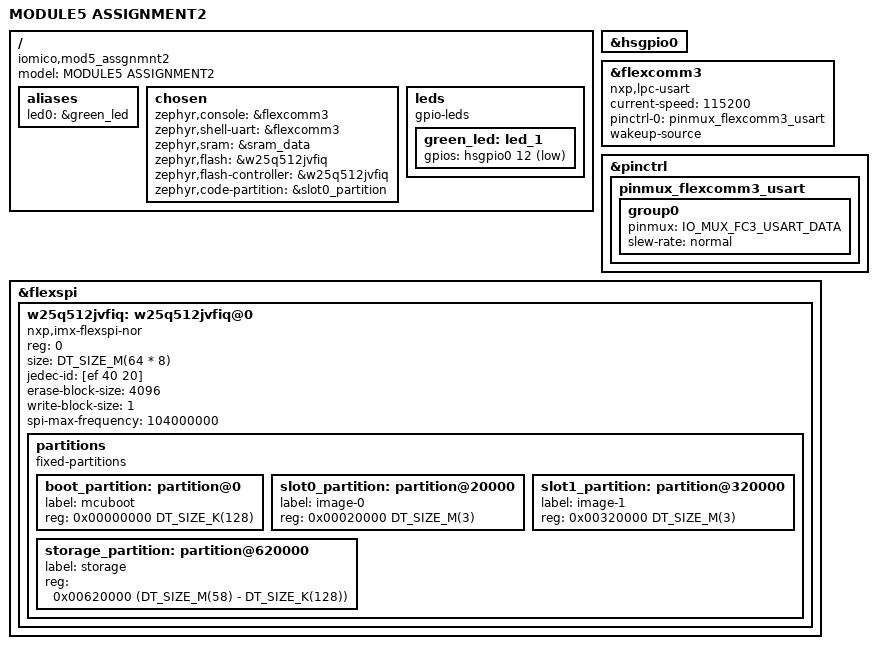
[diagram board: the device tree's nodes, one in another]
/dts-v1/;

#include <nxp/nxp_rw6xx.dtsi>
#include <nxp/rw/RW612-pinctrl.h>

/ {
	model = "MODULE5 ASSIGNMENT2";
	compatible = "iomico,mod5_assgnmnt2";

	aliases {
		led0 = &green_led;
	};

	chosen {
		zephyr,console = &flexcomm3;
		zephyr,shell-uart = &flexcomm3;
	};

	chosen {
		zephyr,sram = &sram_data;
		zephyr,flash = &w25q512jvfiq;
		zephyr,flash-controller = &w25q512jvfiq;
		zephyr,code-partition = &slot0_partition;
		zephyr,console = &flexcomm3;
	};

	leds {
		compatible = "gpio-leds";
		green_led: led_1 {
			gpios = <&hsgpio0 12 GPIO_ACTIVE_LOW>;
		};
	};
};

&hsgpio0 {
	status = "okay";
};

&flexcomm3 {
	compatible = "nxp,lpc-usart";
	status = "okay";
	current-speed = <115200>;
	pinctrl-0 = <&pinmux_flexcomm3_usart>;
	pinctrl-names = "default";
	wakeup-source;
};

&pinctrl {
	pinmux_flexcomm3_usart: pinmux_flexcomm3_usart {
		group0 {
			pinmux = <IO_MUX_FC3_USART_DATA>;
			slew-rate = "normal";
		};
	};
};

&flexspi {
	status = "okay";

	/* Winbond external flash */
	w25q512jvfiq: w25q512jvfiq@0 {
		compatible = "nxp,imx-flexspi-nor";
		reg = <0>;
		size = <DT_SIZE_M(64 * 8)>;
		status = "okay";
		jedec-id = [ef 40 20];
		erase-block-size = <4096>;
		write-block-size = <1>;
		spi-max-frequency = <104000000>;

		partitions {
			compatible = "fixed-partitions";
			#address-cells = <1>;
			#size-cells = <1>;

			/*
			 * Partition sizes must be aligned
			 * to the flash memory sector size of 4KB.
			 */
			boot_partition: partition@0 {
				label = "mcuboot";
				reg = <0x00000000 DT_SIZE_K(128)>;
			};
			slot0_partition: partition@20000 {
				label = "image-0";
				reg = <0x00020000 DT_SIZE_M(3)>;
			};
			slot1_partition: partition@320000 {
				label = "image-1";
				reg = <0x00320000 DT_SIZE_M(3)>;
			};
			storage_partition: partition@620000 {
				label = "storage";
				reg = <0x00620000 (DT_SIZE_M(58) - DT_SIZE_K(128))>;
			};
		};
	};
};
